# YTM32B1HA0 register map
Vendor: YTMicro; File version: 1.0
CPU: little endian, MPU, FPU, 2 interrupt priority bits
Registers are 32-bit, read-write, reset 0x0 unless marked. A register's access mark holds for its fields unless they carry their own. Offsets are from the block's base; [hi:lo] are bit positions; {n}, {i} and the like mark numbered series; 'fields as' and 'values as' point back to an identical list.

## ENET (part 2 of 10) — Ethernet Quality-of-Service
Base 0x401E4000; register names take the prefix ENET_
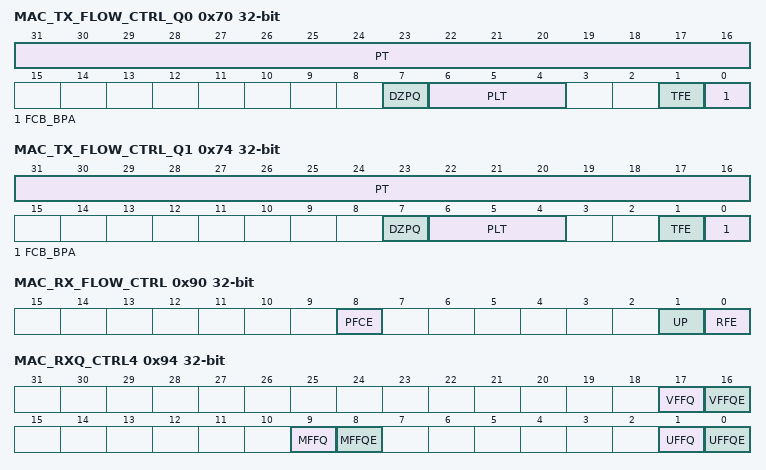
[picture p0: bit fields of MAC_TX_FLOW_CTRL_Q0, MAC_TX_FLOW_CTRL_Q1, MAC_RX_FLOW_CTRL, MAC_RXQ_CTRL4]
0x70 MAC_TX_FLOW_CTRL_Q0 — The Flow Control register controls the generation and reception of the Control (Pause Command) packets by the Flow control module of the MAC. A Write to a register with the Busy bit set to 1 triggers the Flow Control block to generate a Pause packet. The fields of the control packet are selected as specified in the 802.3x specification, and the Pause Time value from this register is used in the Pause Time field of the control packet. The Busy bit remains set until the control packet is transferred onto the cable. The application must make sure that the Busy bit is cleared before writing to the register. When the PFCE bit in the MAC_Rx_Flow_Ctrl register is enabled, this register controls the generation of Priority Flow Control (PFC) frames with priorities mapped according to PSRQ0 in the MAC_Rx- Q_Ctrl2 register.
  [31:16] PT — This field holds the value to be used in the Pause Time field in the Tx control packet. If the Pause Time bits are configured to be double-synchronized to the (G)MII clock domain, consecutive writes to this register should be performed only after at least four clock cycles in the destination clock domain.
  [7] DZPQ — When this bit is set, it disables the automatic generation of the zero-quanta Pause packets on de-assertion of the flow-control signal from the FIFO layer (MTL or external sideband flow control signal sbd_flowctrl_i or mti_flowctrl_i). When this bit is reset, normal operation with automatic zero-quanta Pause packet generation is enabled.
    0=Zero-Quanta Pause packet generation is enabled; 1=Zero-Quanta Pause packet generation is disabled
  [6:4] PLT — This field configures the threshold of the Pause timer at which the input flow control signal mti_flowctrl_i (or sbd_flowctrl_i) is checked for automatic retransmission of the Pause packet. The threshold values should be always less than the Pause Time configured in Bits[31:16]. For example, if PT = 100H (256 slot times), and PLT = 001, a second Pause packet is automatically transmitted if the mti_flowctrl_i signal is asserted at 228 (256-28) slot times after the first Pause packet is transmitted. The following list provides the threshold values for different values. The slot time is defined as the time taken to transmit 512 bits (64 bytes) on the GMII or MII interface. This (approximate) computation is based on the packet size (64, 1518, 2000, 9018, 16384, or 32768) + 2 Pause Packet Size + IPG in Slot Times.
    0=Pause Time minus 4 Slot Times (PT -4 slot times); 1=Pause Time minus 28 slot times (PT -28 slot times); 2=Pause Time minus 36 Slot Times (PT -36 slot times); 3=Pause Time minus 144 Slot Times (PT -144 slot times); 4=Pause Time minus 256 Slot Times (PT -256 slot times); 5=Pause Time minus 512 Slot Times (PT -512 slot times)
  [1] TFE — Full-Duplex Mode: In the full-duplex mode, when this bit is set, the MAC enables the flow control operation to Tx Pause packets. When this bit is reset, the flow control operation in the MAC is disabled, and the MAC does not transmit any Pause packets. Half-Duplex Mode: In the half-duplex mode, when this bit is set, the MAC enables the backpressure operation. When this bit is reset, the backpressure feature is disabled.
    0=Transmit Flow Control is disabled; 1=Transmit Flow Control is enabled
  [0] FCB_BPA — This bit initiates a Pause packet in the full-duplex mode and activates the backpressure function in the half-duplex mode if the TFE bit is set. Full-Duplex Mode: In the full-duplex mode, this bit should be read as 1'b0 before writing to this register. To initiate a Pause packet, the application must set this bit to 1'b1. During Control packet transfer, this bit continues to be set to indicate that a packet transmission is in progress. When Pause packet transmission is complete, the MAC resets this bit to 1'b0. You should not write to this register until this bit is cleared. Half-Duplex Mode: When this bit is set (and TFE bit is set) in the half-duplex mode, the MAC asserts the backpressure. During backpressure, when the MAC receives a new packet, the transmitter starts sending a JAM pattern resulting in a collision. This control register bit is logically ORed with the mti_flowctrl_i input signal for the backpressure function. When the MAC is configured for the full-duplex mode, the BPA is automatically disabled. Access restriction applies. Setting 1 sets. Self-cleared. Setting 0 has no effect.
    0=Flow Control Busy or Backpressure Acti- vate is disabled; 1=Flow Control Busy or Backpressure Acti- vate is enabled
0x74 MAC_TX_FLOW_CTRL_Q1 — The Flow Control register controls the generation and reception of the Control (Pause Command) packets by the Flow control module of the MAC. A Write to a register with the Busy bit set to 1 triggers the Flow Control block to generate a Pause packet. The fields of the control packet are selected as specified in the 802.3x specification, and the Pause Time value from this register is used in the Pause Time field of the control packet. The Busy bit remains set until the control packet is transferred onto the cable. The application must make sure that the Busy bit is cleared before writing to the register. When the PFCE bit in the MAC_Rx_Flow_Ctrl register is enabled, this register controls the generation of Priority Flow Control (PFC) frames with priorities mapped according to PSRQ0 in the MAC_Rx- Q_Ctrl2 register.
  fields as MAC_TX_FLOW_CTRL_Q0
0x90 MAC_RX_FLOW_CTRL — The Receive Flow Control register controls the pausing of MAC Transmit based on the received Pause packet.
  [8] PFCE — When this bit is set, it enables generation and reception of priority-based flow control (PFC) packets. When this bit is reset, it enables generation and reception of 802.3x Pause control packets.
    0=Priority Based Flow Control is disabled; 1=Priority Based Flow Control is enabled
  [1] UP — A pause packet is processed when it has the unique multicast address specified in the IEEE 802.3. When this bit is set, the MAC can also detect Pause packets with unicast address of the station. This unicast address should be as specified in MAC_Address0_High and MAC_Address0_Low. When this bit is reset, the MAC only detects Pause packets with unique multicast address. Note: The MAC does not process a Pause packet if the multicast address is different from the unique multicast address. This is also applicable to the received PFC packet when the Priority Flow Control (PFC) is enabled. The unique multicast address (0x01_80_C2_00_00_01) is as specified in IEEE 802.1 Qbb-2011.
    0=Unicast Pause Packet Detect is disabled; 1=Unicast Pause Packet Detect is enabled
  [0] RFE — When this bit is set and the MAC is operating in full-duplex mode, the MAC decodes the received Pause packet and disables its transmitter for a specified (Pause) time. When this bit is reset or the MAC is operating in half-duplex mode, the decode function of the Pause packet is disabled. When PFC is enabled, flow control is enabled for PFC packets. The MAC decodes the received PFC packet and disables the Transmit queue, with matching priorities, for a duration of received Pause time.
    0=Receive Flow Control is disabled; 1=Receive Flow Control is enabled
0x94 MAC_RXQ_CTRL4 — The Receive Queue Control 4 register controls the routing of unicast and multicast packets that fail the Destination or Source address filter to the Rx queues.
  [17] VFFQ — This field holds the Rx queue number to which the tagged packets failing the Destination or Source Address filter (and UFFQE/MFFQE not enabled) or failing the VLAN tag filter must be routed to. This field is valid only when the VFFQE bit is set.
  [16] VFFQE — When this bit is set, the tagged packets which fail the Destination or Source address filter or fail the VLAN tag filter, are routed to the Rx Queue Number programmed in the VFFQ. When this bit is reset, the tagged packets which fail the Destination or Source address filter or fail the VLAN tag filter are routed based on other routing options. This bit is valid only when the RA bit of the MAC_Packet_Filter register is set.
    0=VLAN Tag Filter Fail Packets Queuing is disabled; 1=VLAN Tag Filter Fail Packets Queuing is enabled
  [9] MFFQ — This field holds the Rx queue number to which the Multicast packets failing the Destination or Source Address filter are routed to. This field is valid only when the MFFQE bit is set.
  [8] MFFQE — When this bit is set, the Multicast packets which fail the Destination or Source address filter is routed to the Rx Queue Number programmed in the MFFQ. When this bit is reset, the Multicast packets which fail the Destination or Source address filter is routed based on other routing options. This bit is valid only when the RA bit of the MAC_Packet_Filter register is set.
    0=Multicast Address Filter Fail Packets Queuing is disabled; 1=Multicast Address Filter Fail Packets Queuing is enabled
  [1] UFFQ — This field holds the Rx queue number to which the Unicast packets failing the Destination or Source Address filter are routed to. This field is valid only when the UFFQE bit is set.
  [0] UFFQE — When this bit is set, the Unicast packets which fail the Destination or Source address filter is routed to the Rx Queue Number programmed in the UFFQ. When this bit is reset, the Unicast packets which fail the Destination or Source address filter is routed based on other routing options. This bit is valid only when the RA bit of the MAC_Packet_Filter register is set.
    0=Unicast Address Filter Fail Packets Queuing is disabled; 1=Unicast Address Filter Fail Packets Queuing is enabled
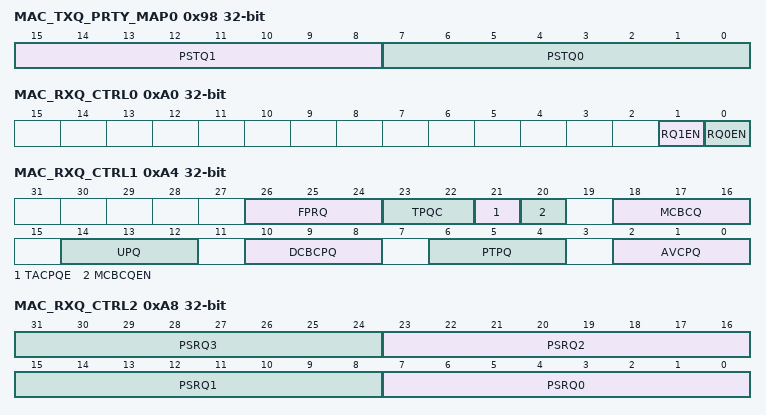
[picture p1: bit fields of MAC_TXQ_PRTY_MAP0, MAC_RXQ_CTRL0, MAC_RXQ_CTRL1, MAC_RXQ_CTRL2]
0x98 MAC_TXQ_PRTY_MAP0 — The Transmit Queue Priority Mapping 0 register contains the priority values assigned to Tx Queue 0 through Tx Queue 0~1.
  [15:8] PSTQ1 — This field holds the priorities assigned to Tx Queue 1 by the software. This field determines if Tx Queue 1 should be blocked from transmitting specified pause time when a PFC packet is received with priorities matching the priorities programmed in this field. If the content of this field is not mutually exclusive to corresponding fields of other Transmit queues, that is, same priority is mapped to multiple Tx queues, the MAC blocks all queues with matching priority for specified time.
  [7:0] PSTQ0 — This field holds the priorities assigned to Tx Queue 0 by the software. This field determines if Tx Queue 0 should be blocked from transmitting specified pause time when a PFC packet is received with priorities matching the priorities programmed in this field. If the content of this field is not mutually exclusive to corresponding fields of other Transmit queues, that is, same priority is mapped to multiple Tx queues, the MAC blocks all queues with matching priority for specified time.
0xA0 MAC_RXQ_CTRL0 — The Receive Queue Control 0 register controls the queue management in the MAC Receiver.Note: In multiple Rx queues configuration, all the queues are disabled by default. Enable the Rx queue by programming the corresponding field in this register.
  [1] RQ1EN — This field indicates whether Rx Queue 1 is enabled for AV or DCB.
    0=Queue not enabled; 1=Queue enabled for AV; 2=Queue enabled for DCB/Generic
  [0] RQ0EN — This field indicates whether Rx Queue 0 is enabled for AV or DCB.
    values as RQ1EN
0xA4 MAC_RXQ_CTRL1 — The Receive Queue Control 1 register controls the routing of multicast, broadcast, AV, DCB, and untagged packets to the Rx queues.
  [26:24] FPRQ — This field holds the Rx queue number to which the residual preemption frames must be forwarded. Preemption frames that are tagged and pass the SA/DA/VLAN filtering are routed based on PSRQ and all other frames are treated as residual frames and is routed to the queue number mentioned in this field. The Queue-0 is used as a default queue for express frames, so this field cannot be programmed to a value 0.
  [23:22] TPQC
    0=VLAN Tagged PTPoE packets are routed as generic VLAN Tagged packet (based on PSRQ for only non-AV enabled Rx Queues); 1=VLAN Tagged PTPoE packets are routed to Rx Queue specified by PTPQ field (That Rx Queue can be enabled for AV or non-AV traffic); 2=VLAN Tagged PTPoE packets are routed to only AV enabled Rx Queues based on PSRQ
  [21] TACPQE — When set, the MAC routes the received Tagged AV Control packets to the Rx queue specified by AVCPQ field. When reset, the MAC routes the received Tagged AV Control packets based on the tag priority matching the PSRQ fields in MAC_RxQ_Ctrl2 and MAC_RxQ_Ctrl3 registers.
    0=Tagged AV Control Packets Queuing is disabled; 1=Tagged AV Control Packets Queuing is enabled
  [20] MCBCQEN — This bit specifies that Multicast or Broadcast packets routing to the Rx Queue is enabled and the Multicast or Broadcast packets must be routed to Rx Queue specified in MCBCQ field.
    0=Multicast and Broadcast Queue is disabled; 1=Multicast and Broadcast Queue is enabled
  [18:16] MCBCQ — This field specifies the Rx Queue onto which Multicast or Broadcast Packets are routed. Any Rx Queue enabled for Generic/DCB/AV traffic can be used to route the Multicast or Broadcast Packets.
    {v}=Receive Queue {v} (v=0..7)
  [14:12] UPQ — This field indicates the Rx Queue to which Untagged Packets are to be routed. Any Rx Queue enabled for Generic/DCB/AV traffic can be used to route the Untagged Packets.
    {v}=Receive Queue {v} (v=0..7)
  [10:8] DCBCPQ — This field specifies the Rx queue on which the received DCB control packets are routed. The DCB data packets are routed based on the PSRQ field of the Transmit Flow Control Register of corresponding queue.
    {v}=Receive Queue {v} (v=0..7)
  [6:4] PTPQ — This field specifies the Rx queue on which the PTP packets sent over the Ethernet payload (not over IPv4 or IPv6) are routed. When the AV8021ASMEN bit of MAC_Timestamp_Control register is set, only untagged PTP over Ethernet packets are routed on an Rx Queue. If the bit is not set, then based on programming of TPQC field, both tagged and untagged PTPoE packets can be routed to this Rx Queue.
    {v}=Receive Queue {v} (v=0..7)
  [2:0] AVCPQ — This field specifies the Receive queue on which the received AV tagged and untagged control packets are routed. The AV tagged (when TACPQE bit is set) and untagged control packets are routed to Receive queue specified by this field.
    {v}=Receive Queue {v} (v=0..7)
0xA8 MAC_RXQ_CTRL2 — This register controls the routing of tagged packets based on the USP (user Priority) field of the received packets to the RxQueues 0 to 3.
  [8n+7:8n] PSRQ{n} (n=0..3) — This field decides the priorities assigned to Rx Queue {n}. All packets with priorities that match the values set in this field are routed to Rx Queue {n}. For example, if PSRQ{n}[6, 3] are set, packets with USP field equal to 3 or 6 are routed to Rx Queue {n}. The software must ensure that the content of this field is mutually exclusive to the PSRQ fields for other queues, that is, the same priority is not mapped to multiple Rx queues. When the DCB feature is selected, this field also determines the priorities to be included in the PFC packet sent to remote station when Rx Queue {n} crosses the flow control threshold settings.
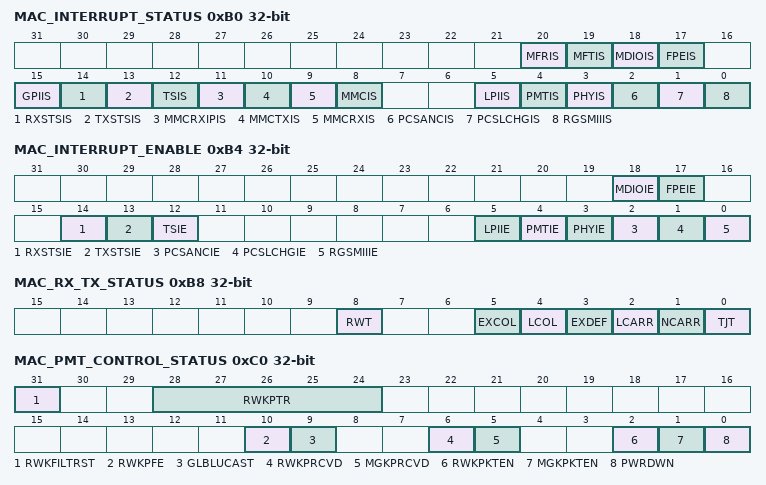
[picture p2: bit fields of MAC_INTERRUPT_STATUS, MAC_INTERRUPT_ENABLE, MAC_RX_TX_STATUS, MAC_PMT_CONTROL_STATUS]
0xB0 MAC_INTERRUPT_STATUS ro — The Interrupt Status register contains the status of interrupts.
  [20] MFRIS rw — This bit is set high when an interrupt is generated in the MMC FPE Receive Interrupt Register. This bit is cleared when all bits in this interrupt register are cleared. This bit is valid only when you select the Enable MAC Management Counters (MMC) option along with FPE support.
    0=MMC FPE Receive Interrupt status not active; 1=MMC FPE Receive Interrupt status active
  [19] MFTIS rw — This bit is set high when an interrupt is generated in the MMC FPE Transmit Interrupt Register. This bit is cleared when all bits in this interrupt register are cleared. This bit is valid only when you select the Enable MAC Management Counters (MMC) option along with FPE support.
    0=MMC FPE Transmit Interrupt status not active; 1=MMC FPE Transmit Interrupt status active
  [18] MDIOIS rw — This bit indicates an interrupt event after the completion of MDIO operation. To reset this bit, the application has to read this bit/Write 1 to this bit when RCWE bit of MAC_CSR_SW_Ctrl register is set. Access restriction applies. Clears on read (or write of 1 when RCWE bit in MAC_CSR_SW_Ctrl register is set). Self-set to 1 on internal event.
    0=MDIO Interrupt status not active; 1=MDIO Interrupt status active
  [17] FPEIS rw — This bit indicates an interrupt event during the operation of Frame Preemption (Bits[19:16] of MAC_FPE_CTRL_STS register is set). To reset this bit, the application must clear the event in MAC_FPE_CTRL_STS that has caused the Interrupt.
    0=Frame Preemption Interrupt status not active; 1=Frame Preemption Interrupt status active
  [15] GPIIS rw — When the GPIO feature is enabled, this bit is set when any active event (LL or LH) occurs on the GPIS field of the MAC_GPIO_Status register and the corresponding GPIE bit is enabled in the MAC_GPIO_Control register. This bit is cleared on reading lane 0 (GPIS) of the MAC_GPIO_Status register.
    0=GPI Interrupt status not active; 1=GPI Interrupt status active
  [14] RXSTSIS rw — This bit indicates the status of received packets. This bit is set when the RWT bit is set in the MAC_Rx_Tx_Status register. This bit is cleared when the corresponding interrupt source bit is read (or corresponding interrupt source bit is written to 1 when RCWE bit of MAC_CSR_SW_Ctrl register is set) in the MAC_Rx_Tx_Status register.
    0=Receive Interrupt status not active; 1=Receive Interrupt status active
  [13] TXSTSIS rw — This bit indicates the status of transmitted packets. This bit is set when any of the following bits is set in the MAC_Rx_Tx_Status register: ■ Excessive Collision (EXCOL) ■ Late Collision (LCOL) ■ Excessive Deferral (EXDEF) ■ Loss of Carrier (LCARR) ■ No Carrier (NCARR) ■ Jabber Timeout (TJT) This bit is cleared when the corresponding interrupt source bit is read (or corresponding interrupt source bit is written to 1 when RCWE bit of MAC_CSR_SW_Ctrl register is set) in the MAC_Rx_Tx_Status register.
    0=Transmit Interrupt status not active; 1=Transmit Interrupt status active
  [12] TSIS rw — If the Timestamp feature is enabled, this bit is set when any of the following conditions is true: ■ The system time value is equal to or exceeds the value specified in the Target Time High and Low registers. ■ There is an overflow in the Seconds register. ■ The Target Time Error occurred, that is, programmed target time already elapsed. If the Auxiliary Snapshot feature is enabled, this bit is set when the auxiliary snapshot trigger is asserted. In configurations other than EQOS_CORE, when drop transmit status is enabled in MTL, this bit is set when the captured transmit timestamp is updated in the MAC_Tx_Timestamp_Status_Nanoseconds and Mac_TxTimestamp_Status_Seconds registers. When PTP offload feature is enabled, this bit is set when the captured transmit timestamp is updated in the MAC_Tx_Timestamp_Status_Nanoseconds and MAC_Tx_Timestamp_Status_Seconds registers, for PTO generated Delay Request and Pdelay request packets. This bit is cleared when the corresponding interrupt source bit is read (or corresponding interrupt source bit is written to 1 when RCWE bit of MAC_CSR_SW_Ctrl register is set) in the MAC_Timestamp_Status register.
    0=Timestamp Interrupt status not active; 1=Timestamp Interrupt status active
  [11] MMCRXIPIS rw — This bit is set high when an interrupt is generated in the MMC Receive Checksum Offload Interrupt Register. This bit is cleared when all bits in this interrupt register are cleared. This bit is valid only when you select the Enable MAC Management Counters (MMC) and Enable Receive TCP/IP Checksum Check options.
    0=MMC Receive Checksum Offload Interrupt status not active; 1=MMC Receive Checksum Offload Interrupt status active
  [10] MMCTXIS rw — This bit is set high when an interrupt is generated in the MMC Transmit Interrupt Register. This bit is cleared when all bits in this interrupt register are cleared. This bit is valid only when you select the Enable MAC Management Counters (MMC) option.
    0=MMC Transmit Interrupt status not active; 1=MMC Transmit Interrupt status active
  [9] MMCRXIS rw — This bit is set high when an interrupt is generated in the MMC Receive Interrupt Register. This bit is cleared when all bits in this interrupt register are cleared. This bit is valid only when you select the Enable MAC Management Counters (MMC) option.
    0=MMC Receive Interrupt status not active; 1=MMC Receive Interrupt status active
  [8] MMCIS rw — This bit is set high when Bit 11, Bit 10, or Bit 9 is set high. This bit is cleared only when all these bits are low. This bit is valid only when you select the Enable MAC Management Counters (MMC) option.
    0=MMC Interrupt status not active; 1=MMC Interrupt status active
  [5] LPIIS rw — When the Energy Efficient Ethernet feature is enabled, this bit is set for any LPI state entry or exit in the MAC Transmitter or Receiver. This bit is cleared when the corresponding interrupt source bit of MAC_LPI_Control_Status register is read (or corresponding interrupt source bit of MAC_LPI_Control_Status register is written to 1 when RCWE bit of MAC_CSR_SW_Ctrl register is set).
    0=LPI Interrupt status not active; 1=LPI Interrupt status active
  [4] PMTIS rw — This bit is set when a Magic packet or Wake-on-LAN packet is received in the power-down mode (RWKPRCVD and MGKPRCVD bits in MAC_PMT_Control_Status register). This bit is cleared when corresponding interrupt source bit are cleared because of a Read operation to the MAC_PMT_Control_Status register (or corresponding interrupt source bit of MAC_PMT_Control_Status register is written to 1 when RCWE bit of MAC_CSR_SW_Ctrl register is set). This bit is valid only when you select the Enable Power Management option.
    0=PMT Interrupt status not active; 1=PMT Interrupt status active
  [3] PHYIS rw — This bit is set when rising edge is detected on the phy_intr_i input. This bit is cleared when this register is read (or this bit is written to 1 when RCWE bit of MAC_CSR_SW_Ctrl register is set).
    0=PHY Interrupt status not active; 1=PHY Interrupt status active
  [2] PCSANCIS rw — This bit is set when auto-negotiation is completed in the TBI, RTBI, or SGMII PHY interface (see ANC bit in the MAC_AN_Status register). This bit is cleared when the MAC_AN_Status register is read (or ANC bit of MAC_AN_Status register is written to 1 when RCWE bit of MAC_CSR_SW_Ctrl register is set). This bit is valid only when you select the optional TBI, RTBI, or SGMII PHY interface.
    0=PCS Auto-Negotiation has not Completed; 1=PCS Auto-Negotiation Completed
  [1] PCSLCHGIS rw — This bit is set because of any change in Link Status in the TBI, RTBI, or SGMII PHY interface (See LS bit in MAC_AN_Status register). This bit is cleared when the MAC_AN_Status register is read (or LS bit of MAC_AN_Status register is written to 1 when RCWE bit of MAC_CSR_SW_Ctrl register is set). This bit is valid only when you select the optional TBI, RTBI, or SGMII PHY interface.
    0=PCS Link Status has not Changed; 1=PCS Link Status Changed
  [0] RGSMIIIS rw — This bit is set because of any change in value of the Link Status of RGMII or SMII interface (LNKSTS bit in MAC_PHYIF_Control_Status register). This bit is cleared when the MAC_PHYIF_Control_Status register is read (or LNKSTS bit of MAC_PHYIF_Control_Status register is written to 1 when RCWE bit of MAC_CSR_SW_Ctrl register is set). This bit is valid only when you select the optional RGMII or SMII PHY interface.
    0=RGMII or SMII Interrupt Status is not active; 1=RGMII or SMII Interrupt Status is active
0xB4 MAC_INTERRUPT_ENABLE — The Interrupt Enable register contains the masks for generating the interrupts.
  [18] MDIOIE — When this bit is set, it enables the assertion of the interrupt when MDIOIS field is set in the MAC_Interrupt_Status register.
    0=MDIO Interrupt is disabled; 1=MDIO Interrupt is enabled
  [17] FPEIE — When this bit is set, it enables the assertion of the interrupt when FPEIS field is set in the MAC_Interrupt_Status register.
    0=Frame Preemption Interrupt is disabled; 1=Frame Preemption Interrupt is enabled
  [14] RXSTSIE — When this bit is set, it enables the assertion of the interrupt signal because of the setting of RXSTSIS bit in the MAC_Interrupt_Status register.
    0=Receive Status Interrupt is disabled; 1=Receive Status Interrupt is enabled
  [13] TXSTSIE — When this bit is set, it enables the assertion of the interrupt signal because of the setting of TXSTSIS bit in the MAC_Interrupt_Status register.
    0=Transmit Status Interrupt is disabled; 1=Transmit Status Interrupt is enabled
  [12] TSIE — When this bit is set, it enables the assertion of the interrupt signal because of the setting of TSIS bit in MAC_Interrupt_Status register.
    0=Timestamp Interrupt is disabled; 1=Timestamp Interrupt is enabled
  [5] LPIIE — When this bit is set, it enables the assertion of the interrupt signal because of the setting of LPIIS bit in MAC_Interrupt_Status register.
    0=LPI Interrupt is disabled; 1=LPI Interrupt is enabled
  [4] PMTIE — When this bit is set, it enables the assertion of the interrupt signal because of the setting of PMTIS bit in MAC_Interrupt_Status register.
    0=PMT Interrupt is disabled; 1=PMT Interrupt is enabled
  [3] PHYIE — When this bit is set, it enables the assertion of the interrupt signal because of the setting of PHYIS bit in MAC_Interrupt_Status register.
    0=PHY Interrupt is disabled; 1=PHY Interrupt is enabled
  [2] PCSANCIE — When this bit is set, it enables the assertion of the interrupt signal because of the setting of PCSANCIS bit in MAC_Interrupt_Status register.
    0=PCS Auto-Negotiation Complete Interrupt is disabled; 1=PCS Auto-Negotiation Complete Interrupt is enabled
  [1] PCSLCHGIE — When this bit is set, it enables the assertion of the interrupt signal because of the setting of PCSLCHGIS bit in MAC_Interrupt_Status register.
    0=PCS Link Status Changed Interrupt is disabled; 1=PCS Link Status Changed Interrupt is enabled
  [0] RGSMIIIE — When this bit is set, it enables the assertion of the interrupt signal because of the setting of RGSMIIIS bit in MAC_Interrupt_Status register.
    0=RGMII or SMII Interrupt is disabled; 1=RGMII or SMII Interrupt is enabled
0xB8 MAC_RX_TX_STATUS ro — The Receive Transmit Status register contains the Receive and Transmit Error status.
  [8] RWT rw — This bit is set when a packet with length greater than 2,048 bytes is received (10, 240 bytes when Jumbo Packet mode is enabled) and the WD bit is reset in the MAC_Configuration register. This bit is set when a packet with length greater than 16,383 bytes is received and the WD bit is set in the MAC_Configuration register. Access restriction applies. Clears on read (or write of 1 when RCWE bit in MAC_CSR_SW_Ctrl register is set). Self-set to 1 on internal event.
    0=No receive watchdog timeout; 1=Receive watchdog timed out
  [5] EXCOL rw — When the DTXSTS bit is set in the MTL_Operation_Mode register, this bit indicates that the transmission aborted after 16 successive collisions while attempting to transmit the current packet. If the DR bit is set in the MAC_Configuration register, this bit is set after the first collision and the packet transmission is aborted. Access restriction applies. Clears on read (or write of 1 when RCWE bit in MAC_CSR_SW_Ctrl register is set). Self-set to 1 on internal event.
    0=No collision; 1=Excessive collision is sensed
  [4] LCOL rw — When the DTXSTS bit is set in the MTL_Operation_Mode register, this bit indicates that the packet transmission aborted because a collision occurred after the collision window (64 bytes including Preamble in MII mode; 512 bytes including Preamble and Carrier Extension in GMII mode). This bit is not valid if the Underflow error occurs. Access restriction applies. Clears on read (or write of 1 when RCWE bit in MAC_CSR_SW_Ctrl register is set). Self-set to 1 on internal event.
    0=No late collision; 1=Late collision is sensed
  [3] EXDEF rw — When the DTXSTS bit is set in the MTL_Operation_Mode register and the DC bit is set in the MAC_Configuration register, this bit indicates that the transmission ended because of excessive deferral of over 24,288 bit times (155,680 in 1000/2500 Mbps mode or when Jumbo packet is enabled). Access restriction applies. Clears on read (or write of 1 when RCWE bit in MAC_CSR_SW_Ctrl register is set). Self-set to 1 on internal event.
    0=No excessive deferral; 1=Excessive deferral
  [2] LCARR rw — When the DTXSTS bit is set in the MTL_Operation_Mode register, this bit indicates that the loss of carrier occurred during packet transmission, that is, the phy_crs_i signal was inactive for one or more transmission clock periods during packet transmission. This bit is valid only for packets transmitted without collision. Access restriction applies. Clears on read (or write of 1 when RCWE bit in MAC_CSR_SW_Ctrl register is set). Self-set to 1 on internal event.
    0=Carrier is present; 1=Loss of carrier
  [1] NCARR rw — When the DTXSTS bit is set in the MTL_Operation_Mode register, this bit indicates that the carrier signal from the PHY is not present at the end of preamble transmission. Access restriction applies. Clears on read (or write of 1 when RCWE bit in MAC_CSR_SW_Ctrl register is set). Self-set to 1 on internal event.
    0=Carrier is present; 1=No carrier
  [0] TJT rw — This bit indicates that the Transmit Jabber Timer expired which happens when the packet size exceeds 2,048 bytes (10,240 bytes when the Jumbo packet is enabled) and JD bit is reset in the MAC_Configuration register. This bit is set when the packet size exceeds 16,383 bytes and the JD bit is set in the MAC_Configuration register. Access restriction applies. Clears on read (or write of 1 when RCWE bit in MAC_CSR_SW_Ctrl register is set). Self-set to 1 on internal event.
    0=No Transmit Jabber Timeout; 1=Transmit Jabber Timeout occurred
0xC0 MAC_PMT_CONTROL_STATUS
  [31] RWKFILTRST — When this bit is set, the remote wake-up packet filter register pointer is reset to 3'b000. It is automatically cleared after 1 clock cycle. Access restriction applies. Setting 1 sets. Self-cleared. Setting 0 has no effect.
    0=Remote Wake-Up Packet Filter Register Pointer is not Reset; 1=Remote Wake-Up Packet Filter Register Pointer is Reset
  [28:24] RWKPTR — This field gives the current value (0 to 7, 15, or 31 when 4, 8, or 16 Remote Wake-up Packet Filters are selected) of the Remote Wake-up Packet Filter register pointer. When the value of this pointer is equal to maximum for the selected number of Remote Wake-up Packet Filters, the contents of the Remote Wake-up Packet Filter Register are transferred to the clk_rx_i domain when a Write occurs to that register.
  [10] RWKPFE — When this bit is set along with RWKPKTEN, the MAC receiver drops all received frames until it receives the expected Wake-up frame. All frames after that event including the received wake-up frame are forwarded to application. This bit is then self-cleared on receiving the wake-up packet. The application can also clear this bit before the expected wake-up frame is received. In such cases, the MAC reverts to the default behavior where packets received are forwarded to the application. This bit must only be set when RWKPKTEN is set high and PWRDWN is set low. The setting of this bit has no effect when PWRDWN is set high. Note: If Magic Packet Enable and Wake-Up Frame Enable are both set along with setting of this bit and Magic Packet is received prior to wake-up frame, this bit is self-cleared on receiving Magic Packet, the received Magic packet is dropped, and all frames after received Magic Packet are forwarded to application. Access restriction applies. Setting 1 sets. Self-cleared. Setting 0 has no effect.
    0=Remote Wake-Up Packet Forwarding is Disabled; 1=Remote Wake-Up Packet Forwarding is Enabled
  [9] GLBLUCAST — When this bit set, any unicast packet filtered by the MAC (DAF) address recognition is detected as a remote wake-up packet.
    0=Global Unicast is Disabled; 1=Global Unicast is Enabled
  [6] RWKPRCVD — When this bit is set, it indicates that the power management event is generated because of the reception of a remote wake-up packet. This bit is cleared when this register is read. Access restriction applies. Clears on read (or write of 1 when RCWE bit in MAC_CSR_SW_Ctrl register is set). Self-set to 1 on internal event.
    0=No Remote Wake-Up Packet is received; 1=Remote Wake-Up Packet is received
  [5] MGKPRCVD — When this bit is set, it indicates that the power management event is generated because of the reception of a magic packet. This bit is cleared when this register is read. Access restriction applies. Clears on read (or write of 1 when RCWE bit in MAC_CSR_SW_Ctrl register is set). Self-set to 1 on internal event.
    0=No Magic Packet is received; 1=Magic Packet is received
  [2] RWKPKTEN — When this bit is set, a power management event is generated when the MAC receives a remote wake-up packet.
    0=Remote Wake-Up Packet is disabled; 1=Remote Wake-Up Packet is enabled
  [1] MGKPKTEN — When this bit is set, a power management event is generated when the MAC receives a magic packet.
    0=Magic Packet is disabled; 1=Magic Packet is enabled
  [0] PWRDWN — When this bit is set, the MAC receiver drops all received packets until it receives the expected magic packet or remote wake-up packet. This bit is then self-cleared and the power-down mode is disabled. The software can clear this bit before the expected magic packet or remote wake-up packet is received. The packets received by the MAC after this bit is cleared are forwarded to the application. This bit must only be set when the Magic Packet Enable, Global Unicast, or Remote Wake-Up Packet Enable bit is set high. Note: You can gate-off the CSR clock during the power-down mode. However, when the CSR clock is gated-off, you cannot perform any read or write operations on this register. Therefore, the Software cannot clear this bit. Access restriction applies. Setting 1 sets. Self-cleared. Setting 0 has no effect.
    0=Power Down is disabled; 1=Power Down is enabled
0xC4 MAC_RWK_PACKET_FILTER
  [31:0] WKUPFRMFTR — This field contains the various controls of RWK Packet filter.
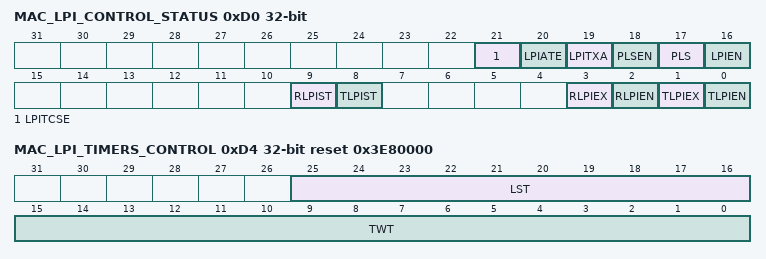
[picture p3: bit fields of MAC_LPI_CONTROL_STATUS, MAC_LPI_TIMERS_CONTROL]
0xD0 MAC_LPI_CONTROL_STATUS — The LPI Control and Status Register controls the LPI functions and provides the LPI interrupt status. The status bits are cleared when this register is read.
  [21] LPITCSE — When this bit is set, the MAC asserts sbd_tx_clk_gating_ctrl_o signal high after it enters Tx LPI mode to indicate that the Tx clock to MAC can be stopped. When this bit is reset, the MAC does not assert sbd_tx_clk_gating_ctrl_o signal high after it enters Tx LPI mode. If RGMII Interface is selected, the Tx clock is required for transmitting the LPI pattern. The Tx Clock cannot be gated and so the LPITCSE bit cannot be programmed.
    0=LPI Tx Clock Stop is disabled; 1=LPI Tx Clock Stop is enabled
  [20] LPIATE — This bit controls the automatic entry of the MAC Transmitter into and exit out of the LPI state. When LPIATE, LPITXA and LPIEN bits are set, the MAC Transmitter enters LPI state only when the complete MAC TX data path is IDLE for a period indicated by the MAC_LPI_Entry_Timer register. After entering LPI state, if the data path becomes non-IDLE (due to a new packet being accepted for transmission), the Transmitter exits LPI state but does not clear LPIEN bit. This enables the re-entry into LPI state when it is IDLE again. When LPIATE is 0, the LPI Auto timer is disabled and MAC Transmitter enters LPI state based on the settings of LPITXA and LPIEN bit descriptions.
    0=LPI Timer is disabled; 1=LPI Timer is enabled
  [19] LPITXA — This bit controls the behavior of the MAC when it is entering or coming out of the LPI mode on the Transmit side. This bit is not functional in the EQOS-CORE configurations in which the Tx clock gating is done during the LPI mode. If the LPITXA and LPIEN bits are set to 1, the MAC enters the LPI mode only after all outstanding packets (in the core) and pending packets (in the application interface) have been transmitted. The MAC comes out of the LPI mode when the application sends any packet for transmission or the application issues a Tx FIFO Flush command. In addition, the MAC automatically clears the LPIEN bit when it exits the LPI state. If Tx FIFO Flush is set in the FTQ bit of MTL_TxQ0_Operation_Mode register, when the MAC is in the LPI mode, it exits the LPI mode. When this bit is 0, the LPIEN bit directly controls behavior of the MAC when it is entering or coming out of the LPI mode.
    0=LPI Tx Automate is disabled; 1=LPI Tx Automate is enabled
  [18] PLSEN — This bit enables the link status received on the RGMII, SGMII, or SMII Receive paths to be used for activating the LPI LS TIMER. When this bit is set, the MAC uses the link-status bits of the MAC_PHYIF_Control_Status register and the PLS bit for the LPI LS Timer trigger. When this bit is reset, the MAC ignores the link-status bits of the MAC_PHYIF_Control_Status register and takes only the PLS bit.
    0=PHY Link Status is disabled; 1=PHY Link Status is enabled
  [17] PLS — This bit indicates the link status of the PHY. The MAC Transmitter asserts the LPI pattern only when the link status is up (OKAY) at least for the time indicated by the LPI LS TIMER. When this bit is set, the link is considered to be okay (UP) and when this bit is reset, the link is considered to be down.
    0=PHY Link Status is down; 1=PHY Link Status is up
  [16] LPIEN — When this bit is set, it instructs the MAC Transmitter to enter the LPI state. When this bit is reset, it instructs the MAC to exit the LPI state and resume normal transmission. This bit is cleared when the LPITXA bit is set and the MAC exits the LPI state because of the arrival of a new packet for transmission.
    0=LPI state is disabled; 1=LPI state is enabled
  [9] RLPIST — When this bit is set, it indicates that the MAC is receiving the LPI pattern on the GMII or MII interface.
    0=Receive LPI state not detected; 1=Receive LPI state detected
  [8] TLPIST — When this bit is set, it indicates that the MAC is transmitting the LPI pattern on the GMII or MII interface.
    0=Transmit LPI state not detected; 1=Transmit LPI state detected
  [3] RLPIEX — When this bit is set, it indicates that the MAC Receiver has stopped receiving the LPI pattern on the GMII or MII interface, exited the LPI state, and resumed the normal reception. This bit is cleared by a read into this register (or this bit is written to 1 when RCWE bit in MAC_CSR_SW_Ctrl register is set). Note: This bit may not be set if the MAC stops receiving the LPI pattern for a very short duration, such as, less than three clock cycles of CSR clock.
    0=Receive LPI exit not detected; 1=Receive LPI exit detected
  [2] RLPIEN — When this bit is set, it indicates that the MAC Receiver has received an LPI pattern and entered the LPI state. This bit is cleared by a read into this register (or this bit is written to 1 when RCWE bit in MAC_CSR_SW_Ctrl register is set). Note: This bit may not be set if the MAC stops receiving the LPI pattern for a very short duration, such as, less than three clock cycles of CSR clock.
    0=Receive LPI entry not detected; 1=Receive LPI entry detected
  [1] TLPIEX — When this bit is set, it indicates that the MAC transmitter exited the LPI state after the application cleared the LPIEN bit and the LPI TW Timer has expired. This bit is cleared by a read into this register (or this bit is written to 1 when RCWE bit in MAC_CSR_SW_Ctrl register is set).
    0=Transmit LPI exit not detected; 1=Transmit LPI exit detected
  [0] TLPIEN — When this bit is set, it indicates that the MAC Transmitter has entered the LPI state because of the setting of the LPIEN bit. This bit is cleared by a read into this register (or this bit is written to 1 when RCWE bit in MAC_CSR_SW_Ctrl register is set).
    0=Transmit LPI entry not detected; 1=Transmit LPI entry detected
0xD4 MAC_LPI_TIMERS_CONTROL reset 0x3E80000 — The LPI Timers Control register controls the timeout values in the LPI states. It specifies the time for which the MAC transmits the LPI pattern and also the time for which the MAC waits before resuming the normal transmission.
  [25:16] LST — This field specifies the minimum time (in milliseconds) for which the link status from the PHY should be up (OKAY) before the LPI pattern can be transmitted to the PHY. The MAC does not transmit the LPI pattern even when the LPIEN bit is set unless the LPI LS Timer reaches the programmed terminal count. The default value of the LPI LS Timer is 1000 (1 sec) as defined in the IEEE standard.
  [15:0] TWT — This field specifies the minimum time (in microseconds) for which the MAC waits after it stops transmitting the LPI pattern to the PHY and before it resumes the normal transmission. The TLPIEX status bit is set after the expiry of this timer.
0xD8 MAC_LPI_ENTRY_TIMER — This register controls the Tx LPI entry timer. This counter is enabled only when bit[20](LPITE) bit of MAC_LPI_Control_Status is set to 1.
  [19:3] LPIET — This field specifies the time in microseconds the MAC waits to enter LPI mode, after it has transmitted all the frames. This field is valid and used only when LPITE and LPITXA are set to 1. Bits [2:0] are read-only so that the granularity of this timer is in steps of 8 micro-seconds.
0xDC MAC_1US_TIC_COUNTER reset 0x63 — This register controls the generation of the Reference time (1 microsecond tic) for all the LPI timers. This timer has to be programmed by the software initially.
  [11:0] TIC_1US_CNTR — The application must program this counter so that the number of clock cycles of CSR clock is 1us. (Subtract 1 from the value before programming). For example if the CSR clock is 100MHz then this field needs to be programmed to value 100 - 1 = 99 (which is 0x63). This is required to generate the 1US events that are used to update some of the EEE related counters.
